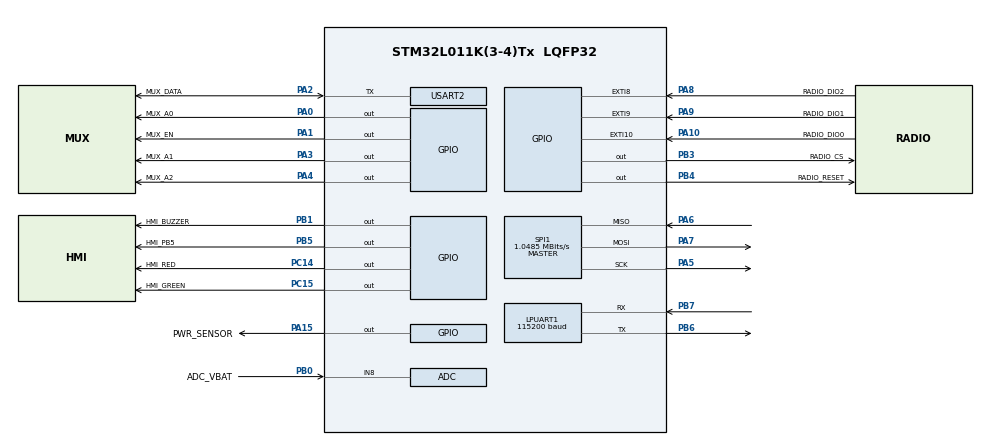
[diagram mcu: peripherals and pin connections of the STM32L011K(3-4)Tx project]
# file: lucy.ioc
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ADC.SamplingTime=ADC_SAMPLETIME_39CYCLES_5
Dma.ADC.0.Direction=DMA_PERIPH_TO_MEMORY
Dma.ADC.0.Instance=DMA1_Channel1
Dma.ADC.0.MemDataAlignment=DMA_MDATAALIGN_HALFWORD
Dma.ADC.0.MemInc=DMA_MINC_ENABLE
Dma.ADC.0.Mode=DMA_NORMAL
Dma.ADC.0.PeriphDataAlignment=DMA_PDATAALIGN_HALFWORD
Dma.ADC.0.PeriphInc=DMA_PINC_DISABLE
Dma.ADC.0.Priority=DMA_PRIORITY_LOW
Dma.Request0=ADC
LPUART1.BaudRate=115200
LPUART1.WordLength=UART_WORDLENGTH_8B
Mcu.Family=STM32L0
Mcu.Name=STM32L011K(3-4)Tx
Mcu.Package=LQFP32
NVIC.ADC1_COMP_IRQn=true\:0\:0\:false\:false\:false\:true\:false
NVIC.DMA1_Channel1_IRQn=true\:0\:0\:false\:false\:false\:false\:false
NVIC.EXTI4_15_IRQn=true\:0\:0\:false\:false\:false\:true\:false
NVIC.RTC_IRQn=true\:0\:0\:false\:false\:false\:true\:false
PA0-CK_IN.GPIO_Label=MUX_A0
PA0-CK_IN.Signal=GPIO_Output
PA1.GPIO_Label=MUX_EN
PA1.Signal=GPIO_Output
PA10.GPIO_Label=RADIO_DIO0
PA10.Signal=GPXTI10
PA13.Mode=Serial_Wire
PA13.Signal=SYS_SWDIO
PA14.Mode=Serial_Wire
PA14.Signal=SYS_SWCLK
PA15.GPIO_Label=PWR_SENSOR
PA15.PinState=GPIO_PIN_RESET
PA15.Signal=GPIO_Output
PA2.GPIO_Label=MUX_DATA
PA2.Mode=Half_duplex(single_wire_mode)
PA2.Signal=USART2_TX
PA3.GPIO_Label=MUX_A1
PA3.Signal=GPIO_Output
PA4.GPIO_Label=MUX_A2
PA4.Signal=GPIO_Output
PA5.GPIO_Speed=GPIO_SPEED_FREQ_HIGH
PA5.Mode=Full_Duplex_Master
PA5.Signal=SPI1_SCK
PA6.GPIO_PuPd=GPIO_PULLUP
PA6.GPIO_Speed=GPIO_SPEED_FREQ_HIGH
PA6.Mode=Full_Duplex_Master
PA6.Signal=SPI1_MISO
PA7.GPIO_Speed=GPIO_SPEED_FREQ_HIGH
PA7.Mode=Full_Duplex_Master
PA7.Signal=SPI1_MOSI
PA8.GPIO_Label=RADIO_DIO2
PA8.Signal=GPXTI8
PA9.GPIO_Label=RADIO_DIO1
PA9.Signal=GPXTI9
PB0.GPIO_Label=ADC_VBAT
PB0.Mode=IN8
PB0.Signal=ADC_IN8
PB1.GPIO_Label=HMI_BUZZER
PB1.Signal=GPIO_Output
PB3.GPIO_Label=RADIO_CS
PB3.Signal=GPIO_Output
PB4.GPIO_Label=RADIO_RESET
PB4.Signal=GPIO_Output
PB5.GPIO_Label=HMI_PB5
PB5.Signal=GPIO_Output
PB6.GPIO_Speed=GPIO_SPEED_FREQ_LOW
PB6.Mode=Asynchronous
PB6.Signal=LPUART1_TX
PB7.GPIO_PuPd=GPIO_PULLUP
PB7.GPIO_Speed=GPIO_SPEED_FREQ_LOW
PB7.Mode=Asynchronous
PB7.Signal=LPUART1_RX
PC14-OSC32_IN.GPIO_Label=HMI_RED
PC14-OSC32_IN.Signal=GPIO_Output
PC15-OSC32_OUT.GPIO_Label=HMI_GREEN
PC15-OSC32_OUT.Signal=GPIO_Output
ProjectManager.HeapSize=0x200
ProjectManager.StackSize=0x400
ProjectManager.TargetToolchain=STM32CubeIDE
RCC.AHBFreq_Value=2097000
RCC.APB1Freq_Value=2097000
RCC.APB1TimFreq_Value=2097000
RCC.APB2Freq_Value=2097000
RCC.APB2TimFreq_Value=2097000
RCC.HSE_VALUE=8000000
RCC.HSI16_VALUE=16000000
RCC.HSI_VALUE=16000000
RCC.LSE_VALUE=32768
RCC.MSI_VALUE=2097000
RCC.SYSCLKFreq_VALUE=2097000
RCC.VCOOutputFreq_Value=48000000
RTC.AsynchPrediv=35
RTC.SynchPrediv=0
RTC.WakeUpClock-WakeUp=RTC_WAKEUPCLOCK_CK_SPRE_16BITS
SPI1.CalculateBaudRate=1.0485 MBits/s
SPI1.Direction=SPI_DIRECTION_2LINES
SPI1.Mode=SPI_MODE_MASTER
SPI1.VirtualType=VM_MASTER
USART2.VirtualMode-Half_duplex(single_wire_mode)=VM_ASYNC
VP_ADC_TempSens_Input.Mode=IN-TempSens
VP_ADC_Vref_Input.Mode=IN-Vrefint
VP_RTC_VS_RTC_Activate.Mode=RTC_Enabled
VP_RTC_VS_RTC_WakeUp_intern.Mode=WakeUp
board=custom

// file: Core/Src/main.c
/* USER CODE BEGIN Header */
/**
  ******************************************************************************
  * @file           : main.c
  * @brief          : Main program body
  ******************************************************************************
  * @attention
  *
  * <h2><center>&copy; Copyright (c) 2020 STMicroelectronics.
  * All rights reserved.</center></h2>
  *
  * This software component is licensed by ST under BSD 3-Clause license,
  * the "License"; You may not use this file except in compliance with the
  * License. You may obtain a copy of the License at:
  *                        opensource.org/licenses/BSD-3-Clause
  *
  ******************************************************************************
  */
/* USER CODE END Header */
#include "main.h"

void SystemClock_Config(void);
static void MX_GPIO_Init(void);
static void MX_DMA_Init(void);
static void MX_LPUART1_UART_Init(void);
static void MX_ADC_Init(void);
static void MX_USART2_UART_Init(void);
static void MX_SPI1_Init(void);
static void MX_RTC_Init(void);

int main(void)
{

  /* MCU Configuration--------------------------------------------------------*/

  /* Reset of all peripherals, Initializes the Flash interface and the Systick. */

  LL_APB2_GRP1_EnableClock(LL_APB2_GRP1_PERIPH_SYSCFG);
  LL_APB1_GRP1_EnableClock(LL_APB1_GRP1_PERIPH_PWR);

  /* System interrupt init*/

  /* Configure the system clock */
  SystemClock_Config();

  /* Initialize all configured peripherals */
  MX_GPIO_Init();
  MX_DMA_Init();
  MX_LPUART1_UART_Init();
  MX_ADC_Init();
  MX_USART2_UART_Init();
  MX_SPI1_Init();
  MX_RTC_Init();
  /* USER CODE BEGIN 2 */
  extern void LucyInit( void );
  LucyInit();
  /* USER CODE END 2 */

  /* Infinite loop */
  while (1)
  {

    /* USER CODE BEGIN 3 */
    extern void LucyLoop( void );
    LucyLoop();
  }
  /* USER CODE END 3 */
}

void SystemClock_Config(void)
{
  LL_FLASH_SetLatency(LL_FLASH_LATENCY_0);
  while(LL_FLASH_GetLatency()!= LL_FLASH_LATENCY_0)
  {
  }
  LL_PWR_SetRegulVoltageScaling(LL_PWR_REGU_VOLTAGE_SCALE1);
  LL_RCC_LSI_Enable();

   /* Wait till LSI is ready */
  while(LL_RCC_LSI_IsReady() != 1)
  {

  }
  LL_RCC_MSI_Enable();

   /* Wait till MSI is ready */
  while(LL_RCC_MSI_IsReady() != 1)
  {

  }
  LL_RCC_MSI_SetRange(LL_RCC_MSIRANGE_5);
  LL_RCC_MSI_SetCalibTrimming(0);
  LL_PWR_EnableBkUpAccess();
  LL_RCC_ForceBackupDomainReset();
  LL_RCC_ReleaseBackupDomainReset();
  LL_RCC_SetRTCClockSource(LL_RCC_RTC_CLKSOURCE_LSI);
  LL_RCC_EnableRTC();
  LL_RCC_SetAHBPrescaler(LL_RCC_SYSCLK_DIV_1);
  LL_RCC_SetAPB1Prescaler(LL_RCC_APB1_DIV_1);
  LL_RCC_SetAPB2Prescaler(LL_RCC_APB2_DIV_1);
  LL_RCC_SetSysClkSource(LL_RCC_SYS_CLKSOURCE_MSI);

   /* Wait till System clock is ready */
  while(LL_RCC_GetSysClkSource() != LL_RCC_SYS_CLKSOURCE_STATUS_MSI)
  {

  }

  LL_Init1msTick(2097000);

  LL_SetSystemCoreClock(2097000);
  LL_RCC_SetUSARTClockSource(LL_RCC_USART2_CLKSOURCE_PCLK1);
  LL_RCC_SetLPUARTClockSource(LL_RCC_LPUART1_CLKSOURCE_PCLK1);
}

static void MX_ADC_Init(void)
{

  LL_ADC_REG_InitTypeDef ADC_REG_InitStruct = {0};
  LL_ADC_InitTypeDef ADC_InitStruct = {0};

  LL_GPIO_InitTypeDef GPIO_InitStruct = {0};

  /* Peripheral clock enable */
  LL_APB2_GRP1_EnableClock(LL_APB2_GRP1_PERIPH_ADC1);

  LL_IOP_GRP1_EnableClock(LL_IOP_GRP1_PERIPH_GPIOB);
  /**ADC GPIO Configuration
  PB0   ------> ADC_IN8
  */
  GPIO_InitStruct.Pin = ADC_VBAT_Pin;
  GPIO_InitStruct.Mode = LL_GPIO_MODE_ANALOG;
  GPIO_InitStruct.Pull = LL_GPIO_PULL_NO;
  LL_GPIO_Init(ADC_VBAT_GPIO_Port, &GPIO_InitStruct);

  /* ADC DMA Init */

  /* ADC Init */
  LL_DMA_SetPeriphRequest(DMA1, LL_DMA_CHANNEL_1, LL_DMA_REQUEST_0);

  LL_DMA_SetDataTransferDirection(DMA1, LL_DMA_CHANNEL_1, LL_DMA_DIRECTION_PERIPH_TO_MEMORY);

  LL_DMA_SetChannelPriorityLevel(DMA1, LL_DMA_CHANNEL_1, LL_DMA_PRIORITY_LOW);

  LL_DMA_SetMode(DMA1, LL_DMA_CHANNEL_1, LL_DMA_MODE_NORMAL);

  LL_DMA_SetPeriphIncMode(DMA1, LL_DMA_CHANNEL_1, LL_DMA_PERIPH_NOINCREMENT);

  LL_DMA_SetMemoryIncMode(DMA1, LL_DMA_CHANNEL_1, LL_DMA_MEMORY_INCREMENT);

  LL_DMA_SetPeriphSize(DMA1, LL_DMA_CHANNEL_1, LL_DMA_PDATAALIGN_HALFWORD);

  LL_DMA_SetMemorySize(DMA1, LL_DMA_CHANNEL_1, LL_DMA_MDATAALIGN_HALFWORD);

  /* ADC interrupt Init */
  NVIC_SetPriority(ADC1_COMP_IRQn, 0);
  NVIC_EnableIRQ(ADC1_COMP_IRQn);

  /** Configure Regular Channel
  */
  LL_ADC_REG_SetSequencerChAdd(ADC1, LL_ADC_CHANNEL_8);
  /** Configure Regular Channel
  */
  LL_ADC_REG_SetSequencerChAdd(ADC1, LL_ADC_CHANNEL_TEMPSENSOR);
  LL_ADC_SetCommonPathInternalCh(__LL_ADC_COMMON_INSTANCE(ADC1), LL_ADC_PATH_INTERNAL_TEMPSENSOR);
  /** Configure Regular Channel
  */
  LL_ADC_REG_SetSequencerChAdd(ADC1, LL_ADC_CHANNEL_VREFINT);
  LL_ADC_SetCommonPathInternalCh(__LL_ADC_COMMON_INSTANCE(ADC1), LL_ADC_PATH_INTERNAL_VREFINT);
  /** Common config
  */
  ADC_REG_InitStruct.TriggerSource = LL_ADC_REG_TRIG_SOFTWARE;
  ADC_REG_InitStruct.SequencerDiscont = LL_ADC_REG_SEQ_DISCONT_DISABLE;
  ADC_REG_InitStruct.ContinuousMode = LL_ADC_REG_CONV_SINGLE;
  ADC_REG_InitStruct.DMATransfer = LL_ADC_REG_DMA_TRANSFER_LIMITED;
  ADC_REG_InitStruct.Overrun = LL_ADC_REG_OVR_DATA_PRESERVED;
  LL_ADC_REG_Init(ADC1, &ADC_REG_InitStruct);
  LL_ADC_SetSamplingTimeCommonChannels(ADC1, LL_ADC_SAMPLINGTIME_39CYCLES_5);
  LL_ADC_SetOverSamplingScope(ADC1, LL_ADC_OVS_DISABLE);
  LL_ADC_REG_SetSequencerScanDirection(ADC1, LL_ADC_REG_SEQ_SCAN_DIR_FORWARD);
  LL_ADC_SetCommonFrequencyMode(__LL_ADC_COMMON_INSTANCE(ADC1), LL_ADC_CLOCK_FREQ_MODE_LOW);
  LL_ADC_DisableIT_EOC(ADC1);
  LL_ADC_DisableIT_EOS(ADC1);

   /* Enable ADC internal voltage regulator */
   LL_ADC_EnableInternalRegulator(ADC1);
   /* Delay for ADC internal voltage regulator stabilization. */
   /* Compute number of CPU cycles to wait for, from delay in us. */
   /* Note: Variable divided by 2 to compensate partially */
   /* CPU processing cycles (depends on compilation optimization). */
   /* Note: If system core clock frequency is below 200kHz, wait time */
   /* is only a few CPU processing cycles. */
   uint32_t wait_loop_index;
   wait_loop_index = ((LL_ADC_DELAY_INTERNAL_REGUL_STAB_US * (SystemCoreClock / (100000 * 2))) / 10);
   while(wait_loop_index != 0)
     {
   wait_loop_index--;
     }
  ADC_InitStruct.Clock = LL_ADC_CLOCK_SYNC_PCLK_DIV1;
  ADC_InitStruct.Resolution = LL_ADC_RESOLUTION_12B;
  ADC_InitStruct.DataAlignment = LL_ADC_DATA_ALIGN_RIGHT;
  ADC_InitStruct.LowPowerMode = LL_ADC_LP_MODE_NONE;
  LL_ADC_Init(ADC1, &ADC_InitStruct);

}

static void MX_LPUART1_UART_Init(void)
{

  LL_LPUART_InitTypeDef LPUART_InitStruct = {0};

  LL_GPIO_InitTypeDef GPIO_InitStruct = {0};

  /* Peripheral clock enable */
  LL_APB1_GRP1_EnableClock(LL_APB1_GRP1_PERIPH_LPUART1);

  LL_IOP_GRP1_EnableClock(LL_IOP_GRP1_PERIPH_GPIOB);
  /**LPUART1 GPIO Configuration
  PB6   ------> LPUART1_TX
  PB7   ------> LPUART1_RX
  */
  GPIO_InitStruct.Pin = LL_GPIO_PIN_6;
  GPIO_InitStruct.Mode = LL_GPIO_MODE_ALTERNATE;
  GPIO_InitStruct.Speed = LL_GPIO_SPEED_FREQ_LOW;
  GPIO_InitStruct.OutputType = LL_GPIO_OUTPUT_PUSHPULL;
  GPIO_InitStruct.Pull = LL_GPIO_PULL_NO;
  GPIO_InitStruct.Alternate = LL_GPIO_AF_6;
  LL_GPIO_Init(GPIOB, &GPIO_InitStruct);

  GPIO_InitStruct.Pin = LL_GPIO_PIN_7;
  GPIO_InitStruct.Mode = LL_GPIO_MODE_ALTERNATE;
  GPIO_InitStruct.Speed = LL_GPIO_SPEED_FREQ_LOW;
  GPIO_InitStruct.OutputType = LL_GPIO_OUTPUT_PUSHPULL;
  GPIO_InitStruct.Pull = LL_GPIO_PULL_UP;
  GPIO_InitStruct.Alternate = LL_GPIO_AF_6;
  LL_GPIO_Init(GPIOB, &GPIO_InitStruct);

  LPUART_InitStruct.BaudRate = 115200;
  LPUART_InitStruct.DataWidth = LL_LPUART_DATAWIDTH_8B;
  LPUART_InitStruct.StopBits = LL_LPUART_STOPBITS_1;
  LPUART_InitStruct.Parity = LL_LPUART_PARITY_NONE;
  LPUART_InitStruct.TransferDirection = LL_LPUART_DIRECTION_TX_RX;
  LPUART_InitStruct.HardwareFlowControl = LL_LPUART_HWCONTROL_NONE;
  LL_LPUART_Init(LPUART1, &LPUART_InitStruct);

}

static void MX_USART2_UART_Init(void)
{

  LL_USART_InitTypeDef USART_InitStruct = {0};

  LL_GPIO_InitTypeDef GPIO_InitStruct = {0};

  /* Peripheral clock enable */
  LL_APB1_GRP1_EnableClock(LL_APB1_GRP1_PERIPH_USART2);

  LL_IOP_GRP1_EnableClock(LL_IOP_GRP1_PERIPH_GPIOA);
  /**USART2 GPIO Configuration
  PA2   ------> USART2_TX
  */
  GPIO_InitStruct.Pin = MUX_DATA_Pin;
  GPIO_InitStruct.Mode = LL_GPIO_MODE_ALTERNATE;
  GPIO_InitStruct.Speed = LL_GPIO_SPEED_FREQ_VERY_HIGH;
  GPIO_InitStruct.OutputType = LL_GPIO_OUTPUT_OPENDRAIN;
  GPIO_InitStruct.Pull = LL_GPIO_PULL_UP;
  GPIO_InitStruct.Alternate = LL_GPIO_AF_4;
  LL_GPIO_Init(MUX_DATA_GPIO_Port, &GPIO_InitStruct);

  USART_InitStruct.BaudRate = 115200;
  USART_InitStruct.DataWidth = LL_USART_DATAWIDTH_8B;
  USART_InitStruct.StopBits = LL_USART_STOPBITS_1;
  USART_InitStruct.Parity = LL_USART_PARITY_NONE;
  USART_InitStruct.TransferDirection = LL_USART_DIRECTION_TX_RX;
  USART_InitStruct.OverSampling = LL_USART_OVERSAMPLING_16;
  LL_USART_Init(USART2, &USART_InitStruct);
  LL_USART_ConfigHalfDuplexMode(USART2);
  LL_USART_Enable(USART2);

}

static void MX_RTC_Init(void)
{

  LL_RTC_InitTypeDef RTC_InitStruct = {0};

  /* Peripheral clock enable */
  LL_RCC_EnableRTC();

  /* RTC interrupt Init */
  NVIC_SetPriority(RTC_IRQn, 0);
  NVIC_EnableIRQ(RTC_IRQn);

  /** Initialize RTC and set the Time and Date
  */
  RTC_InitStruct.HourFormat = LL_RTC_HOURFORMAT_24HOUR;
  RTC_InitStruct.AsynchPrescaler = 35;
  RTC_InitStruct.SynchPrescaler = 0;
  LL_RTC_Init(RTC, &RTC_InitStruct);
  /** Initialize RTC and set the Time and Date
  */
  /** Enable the WakeUp
  */
  LL_RTC_WAKEUP_SetClock(RTC, LL_RTC_WAKEUPCLOCK_CKSPRE);

}

static void MX_SPI1_Init(void)
{

  LL_SPI_InitTypeDef SPI_InitStruct = {0};

  LL_GPIO_InitTypeDef GPIO_InitStruct = {0};

  /* Peripheral clock enable */
  LL_APB2_GRP1_EnableClock(LL_APB2_GRP1_PERIPH_SPI1);

  LL_IOP_GRP1_EnableClock(LL_IOP_GRP1_PERIPH_GPIOA);
  /**SPI1 GPIO Configuration
  PA5   ------> SPI1_SCK
  PA6   ------> SPI1_MISO
  PA7   ------> SPI1_MOSI
  */
  GPIO_InitStruct.Pin = LL_GPIO_PIN_5;
  GPIO_InitStruct.Mode = LL_GPIO_MODE_ALTERNATE;
  GPIO_InitStruct.Speed = LL_GPIO_SPEED_FREQ_HIGH;
  GPIO_InitStruct.OutputType = LL_GPIO_OUTPUT_PUSHPULL;
  GPIO_InitStruct.Pull = LL_GPIO_PULL_NO;
  GPIO_InitStruct.Alternate = LL_GPIO_AF_0;
  LL_GPIO_Init(GPIOA, &GPIO_InitStruct);

  GPIO_InitStruct.Pin = LL_GPIO_PIN_6;
  GPIO_InitStruct.Mode = LL_GPIO_MODE_ALTERNATE;
  GPIO_InitStruct.Speed = LL_GPIO_SPEED_FREQ_HIGH;
  GPIO_InitStruct.OutputType = LL_GPIO_OUTPUT_PUSHPULL;
  GPIO_InitStruct.Pull = LL_GPIO_PULL_UP;
  GPIO_InitStruct.Alternate = LL_GPIO_AF_0;
  LL_GPIO_Init(GPIOA, &GPIO_InitStruct);

  GPIO_InitStruct.Pin = LL_GPIO_PIN_7;
  GPIO_InitStruct.Mode = LL_GPIO_MODE_ALTERNATE;
  GPIO_InitStruct.Speed = LL_GPIO_SPEED_FREQ_HIGH;
  GPIO_InitStruct.OutputType = LL_GPIO_OUTPUT_PUSHPULL;
  GPIO_InitStruct.Pull = LL_GPIO_PULL_NO;
  GPIO_InitStruct.Alternate = LL_GPIO_AF_0;
  LL_GPIO_Init(GPIOA, &GPIO_InitStruct);

  /* SPI1 parameter configuration*/
  SPI_InitStruct.TransferDirection = LL_SPI_FULL_DUPLEX;
  SPI_InitStruct.Mode = LL_SPI_MODE_MASTER;
  SPI_InitStruct.DataWidth = LL_SPI_DATAWIDTH_8BIT;
  SPI_InitStruct.ClockPolarity = LL_SPI_POLARITY_LOW;
  SPI_InitStruct.ClockPhase = LL_SPI_PHASE_1EDGE;
  SPI_InitStruct.NSS = LL_SPI_NSS_SOFT;
  SPI_InitStruct.BaudRate = LL_SPI_BAUDRATEPRESCALER_DIV2;
  SPI_InitStruct.BitOrder = LL_SPI_MSB_FIRST;
  SPI_InitStruct.CRCCalculation = LL_SPI_CRCCALCULATION_DISABLE;
  SPI_InitStruct.CRCPoly = 7;
  LL_SPI_Init(SPI1, &SPI_InitStruct);
  LL_SPI_SetStandard(SPI1, LL_SPI_PROTOCOL_MOTOROLA);

}

static void MX_DMA_Init(void)
{

  /* Init with LL driver */
  /* DMA controller clock enable */
  LL_AHB1_GRP1_EnableClock(LL_AHB1_GRP1_PERIPH_DMA1);

  /* DMA interrupt init */
  /* DMA1_Channel1_IRQn interrupt configuration */
  NVIC_SetPriority(DMA1_Channel1_IRQn, 0);
  NVIC_EnableIRQ(DMA1_Channel1_IRQn);

}

static void MX_GPIO_Init(void)
{
  LL_EXTI_InitTypeDef EXTI_InitStruct = {0};
  LL_GPIO_InitTypeDef GPIO_InitStruct = {0};

  /* GPIO Ports Clock Enable */
  LL_IOP_GRP1_EnableClock(LL_IOP_GRP1_PERIPH_GPIOC);
  LL_IOP_GRP1_EnableClock(LL_IOP_GRP1_PERIPH_GPIOA);
  LL_IOP_GRP1_EnableClock(LL_IOP_GRP1_PERIPH_GPIOB);

  /**/
  LL_GPIO_ResetOutputPin(HMI_RED_GPIO_Port, HMI_RED_Pin);

  /**/
  LL_GPIO_ResetOutputPin(HMI_GREEN_GPIO_Port, HMI_GREEN_Pin);

  /**/
  LL_GPIO_ResetOutputPin(MUX_A0_GPIO_Port, MUX_A0_Pin);

  /**/
  LL_GPIO_ResetOutputPin(MUX_EN_GPIO_Port, MUX_EN_Pin);

  /**/
  LL_GPIO_ResetOutputPin(MUX_A1_GPIO_Port, MUX_A1_Pin);

  /**/
  LL_GPIO_ResetOutputPin(MUX_A2_GPIO_Port, MUX_A2_Pin);

  /**/
  LL_GPIO_ResetOutputPin(HMI_BUZZER_GPIO_Port, HMI_BUZZER_Pin);

  /**/
  LL_GPIO_ResetOutputPin(PWR_SENSOR_GPIO_Port, PWR_SENSOR_Pin);

  /**/
  LL_GPIO_ResetOutputPin(RADIO_CS_GPIO_Port, RADIO_CS_Pin);

  /**/
  LL_GPIO_ResetOutputPin(RADIO_RESET_GPIO_Port, RADIO_RESET_Pin);

  /**/
  LL_GPIO_ResetOutputPin(HMI_PB5_GPIO_Port, HMI_PB5_Pin);

  /**/
  GPIO_InitStruct.Pin = HMI_RED_Pin;
  GPIO_InitStruct.Mode = LL_GPIO_MODE_OUTPUT;
  GPIO_InitStruct.Speed = LL_GPIO_SPEED_FREQ_LOW;
  GPIO_InitStruct.OutputType = LL_GPIO_OUTPUT_PUSHPULL;
  GPIO_InitStruct.Pull = LL_GPIO_PULL_NO;
  LL_GPIO_Init(HMI_RED_GPIO_Port, &GPIO_InitStruct);

  /**/
  GPIO_InitStruct.Pin = HMI_GREEN_Pin;
  GPIO_InitStruct.Mode = LL_GPIO_MODE_OUTPUT;
  GPIO_InitStruct.Speed = LL_GPIO_SPEED_FREQ_LOW;
  GPIO_InitStruct.OutputType = LL_GPIO_OUTPUT_PUSHPULL;
  GPIO_InitStruct.Pull = LL_GPIO_PULL_NO;
  LL_GPIO_Init(HMI_GREEN_GPIO_Port, &GPIO_InitStruct);

  /**/
  GPIO_InitStruct.Pin = MUX_A0_Pin;
  GPIO_InitStruct.Mode = LL_GPIO_MODE_OUTPUT;
  GPIO_InitStruct.Speed = LL_GPIO_SPEED_FREQ_LOW;
  GPIO_InitStruct.OutputType = LL_GPIO_OUTPUT_PUSHPULL;
  GPIO_InitStruct.Pull = LL_GPIO_PULL_NO;
  LL_GPIO_Init(MUX_A0_GPIO_Port, &GPIO_InitStruct);

  /**/
  GPIO_InitStruct.Pin = MUX_EN_Pin;
  GPIO_InitStruct.Mode = LL_GPIO_MODE_OUTPUT;
  GPIO_InitStruct.Speed = LL_GPIO_SPEED_FREQ_LOW;
  GPIO_InitStruct.OutputType = LL_GPIO_OUTPUT_PUSHPULL;
  GPIO_InitStruct.Pull = LL_GPIO_PULL_NO;
  LL_GPIO_Init(MUX_EN_GPIO_Port, &GPIO_InitStruct);

  /**/
  GPIO_InitStruct.Pin = MUX_A1_Pin;
  GPIO_InitStruct.Mode = LL_GPIO_MODE_OUTPUT;
  GPIO_InitStruct.Speed = LL_GPIO_SPEED_FREQ_LOW;
  GPIO_InitStruct.OutputType = LL_GPIO_OUTPUT_PUSHPULL;
  GPIO_InitStruct.Pull = LL_GPIO_PULL_NO;
  LL_GPIO_Init(MUX_A1_GPIO_Port, &GPIO_InitStruct);

  /**/
  GPIO_InitStruct.Pin = MUX_A2_Pin;
  GPIO_InitStruct.Mode = LL_GPIO_MODE_OUTPUT;
  GPIO_InitStruct.Speed = LL_GPIO_SPEED_FREQ_LOW;
  GPIO_InitStruct.OutputType = LL_GPIO_OUTPUT_PUSHPULL;
  GPIO_InitStruct.Pull = LL_GPIO_PULL_NO;
  LL_GPIO_Init(MUX_A2_GPIO_Port, &GPIO_InitStruct);

  /**/
  GPIO_InitStruct.Pin = HMI_BUZZER_Pin;
  GPIO_InitStruct.Mode = LL_GPIO_MODE_OUTPUT;
  GPIO_InitStruct.Speed = LL_GPIO_SPEED_FREQ_LOW;
  GPIO_InitStruct.OutputType = LL_GPIO_OUTPUT_PUSHPULL;
  GPIO_InitStruct.Pull = LL_GPIO_PULL_NO;
  LL_GPIO_Init(HMI_BUZZER_GPIO_Port, &GPIO_InitStruct);

  /**/
  GPIO_InitStruct.Pin = LL_GPIO_PIN_11;
  GPIO_InitStruct.Mode = LL_GPIO_MODE_ANALOG;
  GPIO_InitStruct.Pull = LL_GPIO_PULL_NO;
  LL_GPIO_Init(GPIOA, &GPIO_InitStruct);

  /**/
  GPIO_InitStruct.Pin = LL_GPIO_PIN_12;
  GPIO_InitStruct.Mode = LL_GPIO_MODE_ANALOG;
  GPIO_InitStruct.Pull = LL_GPIO_PULL_NO;
  LL_GPIO_Init(GPIOA, &GPIO_InitStruct);

  /**/
  GPIO_InitStruct.Pin = PWR_SENSOR_Pin;
  GPIO_InitStruct.Mode = LL_GPIO_MODE_OUTPUT;
  GPIO_InitStruct.Speed = LL_GPIO_SPEED_FREQ_LOW;
  GPIO_InitStruct.OutputType = LL_GPIO_OUTPUT_PUSHPULL;
  GPIO_InitStruct.Pull = LL_GPIO_PULL_NO;
  LL_GPIO_Init(PWR_SENSOR_GPIO_Port, &GPIO_InitStruct);

  /**/
  GPIO_InitStruct.Pin = RADIO_CS_Pin;
  GPIO_InitStruct.Mode = LL_GPIO_MODE_OUTPUT;
  GPIO_InitStruct.Speed = LL_GPIO_SPEED_FREQ_LOW;
  GPIO_InitStruct.OutputType = LL_GPIO_OUTPUT_PUSHPULL;
  GPIO_InitStruct.Pull = LL_GPIO_PULL_NO;
  LL_GPIO_Init(RADIO_CS_GPIO_Port, &GPIO_InitStruct);

  /**/
  GPIO_InitStruct.Pin = RADIO_RESET_Pin;
  GPIO_InitStruct.Mode = LL_GPIO_MODE_OUTPUT;
  GPIO_InitStruct.Speed = LL_GPIO_SPEED_FREQ_LOW;
  GPIO_InitStruct.OutputType = LL_GPIO_OUTPUT_PUSHPULL;
  GPIO_InitStruct.Pull = LL_GPIO_PULL_NO;
  LL_GPIO_Init(RADIO_RESET_GPIO_Port, &GPIO_InitStruct);

  /**/
  GPIO_InitStruct.Pin = HMI_PB5_Pin;
  GPIO_InitStruct.Mode = LL_GPIO_MODE_OUTPUT;
  GPIO_InitStruct.Speed = LL_GPIO_SPEED_FREQ_LOW;
  GPIO_InitStruct.OutputType = LL_GPIO_OUTPUT_PUSHPULL;
  GPIO_InitStruct.Pull = LL_GPIO_PULL_NO;
  LL_GPIO_Init(HMI_PB5_GPIO_Port, &GPIO_InitStruct);

  /**/
  LL_SYSCFG_SetEXTISource(LL_SYSCFG_EXTI_PORTA, LL_SYSCFG_EXTI_LINE8);

  /**/
  LL_SYSCFG_SetEXTISource(LL_SYSCFG_EXTI_PORTA, LL_SYSCFG_EXTI_LINE9);

  /**/
  LL_SYSCFG_SetEXTISource(LL_SYSCFG_EXTI_PORTA, LL_SYSCFG_EXTI_LINE10);

  /**/
  LL_GPIO_SetPinPull(RADIO_DIO2_GPIO_Port, RADIO_DIO2_Pin, LL_GPIO_PULL_NO);

  /**/
  LL_GPIO_SetPinPull(RADIO_DIO1_GPIO_Port, RADIO_DIO1_Pin, LL_GPIO_PULL_NO);

  /**/
  LL_GPIO_SetPinPull(RADIO_DIO0_GPIO_Port, RADIO_DIO0_Pin, LL_GPIO_PULL_NO);

  /**/
  LL_GPIO_SetPinMode(RADIO_DIO2_GPIO_Port, RADIO_DIO2_Pin, LL_GPIO_MODE_INPUT);

  /**/
  LL_GPIO_SetPinMode(RADIO_DIO1_GPIO_Port, RADIO_DIO1_Pin, LL_GPIO_MODE_INPUT);

  /**/
  LL_GPIO_SetPinMode(RADIO_DIO0_GPIO_Port, RADIO_DIO0_Pin, LL_GPIO_MODE_INPUT);

  /**/
  EXTI_InitStruct.Line_0_31 = LL_EXTI_LINE_8;
  EXTI_InitStruct.LineCommand = ENABLE;
  EXTI_InitStruct.Mode = LL_EXTI_MODE_IT;
  EXTI_InitStruct.Trigger = LL_EXTI_TRIGGER_RISING;
  LL_EXTI_Init(&EXTI_InitStruct);

  /**/
  EXTI_InitStruct.Line_0_31 = LL_EXTI_LINE_9;
  EXTI_InitStruct.LineCommand = ENABLE;
  EXTI_InitStruct.Mode = LL_EXTI_MODE_IT;
  EXTI_InitStruct.Trigger = LL_EXTI_TRIGGER_RISING;
  LL_EXTI_Init(&EXTI_InitStruct);

  /**/
  EXTI_InitStruct.Line_0_31 = LL_EXTI_LINE_10;
  EXTI_InitStruct.LineCommand = ENABLE;
  EXTI_InitStruct.Mode = LL_EXTI_MODE_IT;
  EXTI_InitStruct.Trigger = LL_EXTI_TRIGGER_RISING;
  LL_EXTI_Init(&EXTI_InitStruct);

  /* EXTI interrupt init*/
  NVIC_SetPriority(EXTI4_15_IRQn, 0);
  NVIC_EnableIRQ(EXTI4_15_IRQn);

}

void Error_Handler(void)
{
}

/************************ (C) COPYRIGHT STMicroelectronics *****END OF FILE****/
